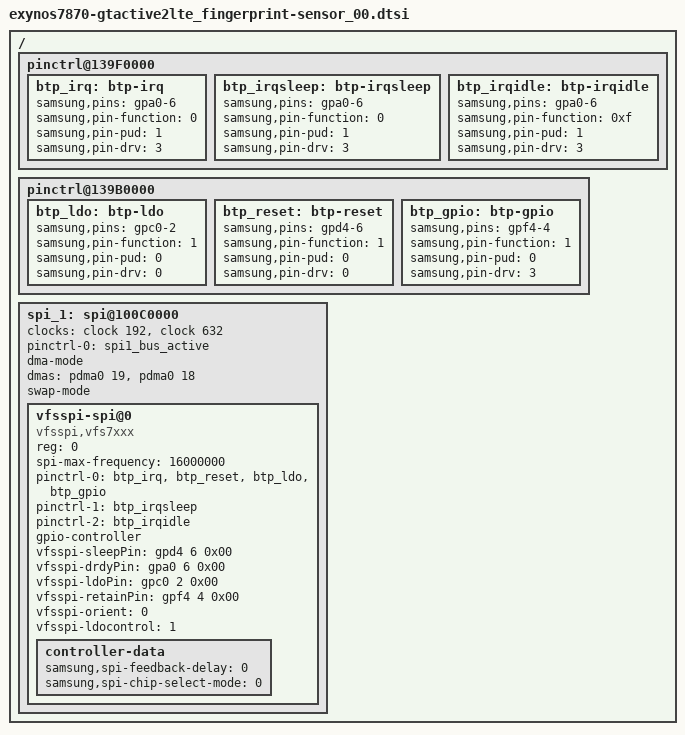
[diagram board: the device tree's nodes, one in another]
/*
 * Copyright (c) 2012-2013, The Linux Foundation. All rights reserved.
 *
 * This program is free software; you can redistribute it and/or modify
 * it under the terms of the GNU General Public License version 2 and
 * only version 2 as published by the Free Software Foundation.
 *
 * This program is distributed in the hope that it will be useful,
 * but WITHOUT ANY WARRANTY; without even the implied warranty of
 * MERCHANTABILITY or FITNESS FOR A PARTICULAR PURPOSE.  See the
 * GNU General Public License for more details.
 */

/ {
	pinctrl@139F0000 {
		btp_irq: btp-irq {
			samsung,pins = "gpa0-6";
			samsung,pin-function = <0>;
			samsung,pin-pud = <1>;
			samsung,pin-drv = <3>;
		};
		btp_irqsleep: btp-irqsleep {
			samsung,pins = "gpa0-6";
			samsung,pin-function = <0>;
			samsung,pin-pud = <1>;
			samsung,pin-drv = <3>;
		};
		btp_irqidle: btp-irqidle {
			samsung,pins = "gpa0-6";
			samsung,pin-function = <0xf>;
			samsung,pin-pud = <1>;
			samsung,pin-drv = <3>;
		};
	};
	pinctrl@139B0000 {
		btp_ldo: btp-ldo {
			samsung,pins = "gpc0-2";
			samsung,pin-function = <1>;
			samsung,pin-pud = <0>;
			samsung,pin-drv = <0>;
		};
		btp_reset: btp-reset {
			samsung,pins = "gpd4-6";
			samsung,pin-function = <1>;
			samsung,pin-pud = <0>;
			samsung,pin-drv = <0>;
		};
		btp_gpio: btp-gpio {
			samsung,pins = "gpf4-4";
			samsung,pin-function = <1>;
			samsung,pin-pud = <0>;
			samsung,pin-drv = <3>;
		};
	};

	spi_1: spi@100C0000 {
		status = "okay";
		#address-cells = <1>;
		#size-cells = <0>;
		clocks = <&clock 192>, <&clock 632>;
		clock-names = "spi", "spi_busclk0";
		pinctrl-names = "default";
		pinctrl-0 = <&spi1_bus_active>;

		dma-mode;
		dmas = <&pdma0 19
			&pdma0 18>;
		dma-names = "tx", "rx";
		swap-mode;
		vfsspi-spi@0 {
			compatible = "vfsspi,vfs7xxx";
			reg = <0>;
			spi-max-frequency = <16000000>;
			pinctrl-names = "default", "sleep", "idle";
			pinctrl-0 = <&btp_irq &btp_reset &btp_ldo &btp_gpio>;
			pinctrl-1 = <&btp_irqsleep>;
			pinctrl-2 = <&btp_irqidle>;

			gpio-controller;
			#gpio-cells = <2>;

			vfsspi-sleepPin = <&gpd4 6 0x00>;
			vfsspi-drdyPin = <&gpa0 6 0x00>;
			vfsspi-ldoPin = <&gpc0 2 0x00>;
			vfsspi-retainPin = <&gpf4 4 0x00>;
			vfsspi-orient = <0>;
			vfsspi-ldocontrol = <1>;
			controller-data {
				samsung,spi-feedback-delay = <0>;
				samsung,spi-chip-select-mode = <0>;
			};
		};
	};
};
